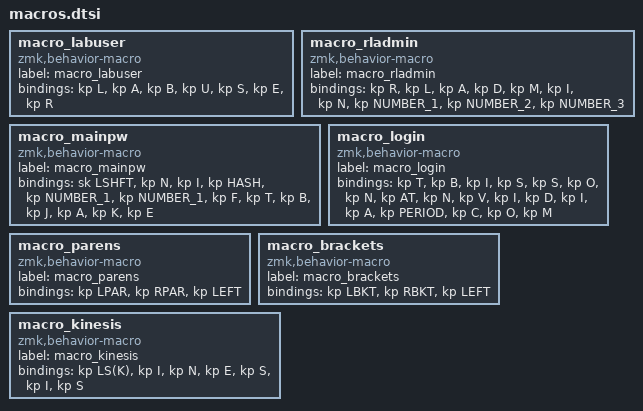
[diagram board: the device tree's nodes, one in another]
macro_labuser: macro_labuser{
compatible = "zmk,behavior-macro";
label = "macro_labuser";
#binding-cells = <0>;
bindings = <&kp L>, <&kp A>, <&kp B>, <&kp U>, <&kp S>, <&kp E>, <&kp R>;
};
macro_rladmin: macro_rladmin{
compatible = "zmk,behavior-macro";
label = "macro_rladmin";
#binding-cells = <0>;
bindings = <&kp R>, <&kp L>, <&kp A>, <&kp D>, <&kp M>, <&kp I>, <&kp N>, <&kp NUMBER_1>, <&kp NUMBER_2>, <&kp NUMBER_3>;
};
macro_mainpw: macro_mainpw{
compatible = "zmk,behavior-macro";
label = "macro_mainpw";
#binding-cells = <0>;
bindings = <&sk LSHFT>, <&kp N>, <&kp I>, <&kp HASH>, <&kp NUMBER_1>, <&kp NUMBER_1>, <&kp F>, <&kp T>, <&kp B>, <&kp J>, <&kp A>, <&kp K>, <&kp E>;
};
macro_login: macro_login{
compatible = "zmk,behavior-macro";
label = "macro_login";
#binding-cells = <0>;
bindings = <&kp T>, <&kp B>, <&kp I>, <&kp S>, <&kp S>, <&kp O>, <&kp N>, <&kp AT>, <&kp N>, <&kp V>, <&kp I>, <&kp D>, <&kp I>, <&kp A>, <&kp PERIOD>, <&kp C>, <&kp O>, <&kp M>;
};
macro_parens: macro_parens{
compatible = "zmk,behavior-macro";
label = "macro_parens";
#binding-cells = <0>;
bindings = <&kp LPAR>, <&kp RPAR>, <&kp LEFT>;
};
macro_brackets: macro_brackets{
compatible = "zmk,behavior-macro";
label = "macro_brackets";
#binding-cells = <0>;
bindings = <&kp LBKT>, <&kp RBKT>, <&kp LEFT>;
};
macro_kinesis: macro_kinesis{
compatible = "zmk,behavior-macro";
label = "macro_kinesis";
#binding-cells = <0>;
bindings = <&kp LS(K)>, <&kp I>, <&kp N>, <&kp E>, <&kp S>, <&kp I>, <&kp S>;
};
